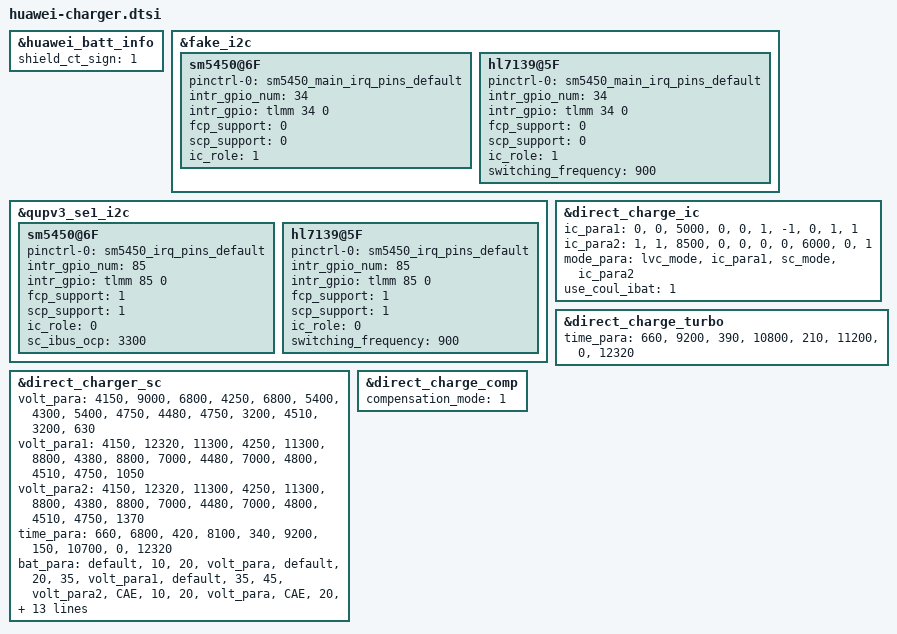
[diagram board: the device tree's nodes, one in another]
&huawei_batt_info {
    shield_ct_sign = <1>;
};

&fake_i2c {
	sm5450@6F{
		pinctrl-0 = <&sm5450_main_irq_pins_default>;
		intr_gpio_num = <34>; /* direct defined GPIO num */
		intr_gpio = <&tlmm 34 0>;
		fcp_support = <0>;
		scp_support = <0>;
		ic_role = <1>;
	};

	hl7139@5F {
		pinctrl-0 = <&sm5450_main_irq_pins_default>;
		intr_gpio_num = <34>; /* direct defined GPIO num */
		intr_gpio = <&tlmm 34 0>;
		fcp_support = <0>;
		scp_support = <0>;
		ic_role = <1>;
		switching_frequency = <900>;

	};
};

&qupv3_se1_i2c {
	sm5450@6F{
		pinctrl-0 = <&sm5450_irq_pins_default>;
		intr_gpio_num = <85>; /* direct defined GPIO num */
		intr_gpio = <&tlmm 85 0>;
		fcp_support = <1>;
		scp_support = <1>;
		ic_role = <0>;
	};

	hl7139@5F {
		pinctrl-0 = <&sm5450_irq_pins_default>;
		intr_gpio_num = <85>; /* direct defined GPIO num */
		intr_gpio = <&tlmm 85 0>;
		fcp_support = <1>;
		scp_support = <1>;
		ic_role = <0>;
		switching_frequency = <900>;

	};
};

&direct_charge_ic {
	/* ic_index  path_index  max_ibat  ibat_sample_point  vbat_sample_point */
	ic_para1 =
		"0", "0", "5000", "0", "0",
		"1", "-1", "0", "1", "1";
	ic_para2 =
		"1", "1", "8500", "0", "0",
		"0", "0", "6000", "0", "1";
	mode_para =
		"lvc_mode", "ic_para1",
		"sc_mode", "ic_para2";
        use_coul_ibat = <1>;
	status = "ok";
};

&direct_charger_sc {
	volt_para =
		"4150", "9000", "6800",
		"4250", "6800", "5400",
		"4300", "5400", "4750",
		"4480", "4750", "3200",
		"4510", "3200", "630";
	volt_para1 =
		"4150", "12320", "11300",
		"4250", "11300", "8800",
		"4380", "8800", "7000",
		"4480", "7000", "4800",
		"4510", "4750", "1050";
	volt_para2 =
		"4150", "12320", "11300",
		"4250", "11300", "8800",
		"4380", "8800", "7000",
		"4480", "7000", "4800",
		"4510", "4750", "1370";
	time_para =
		"660", "6800",
		"420", "8100",
		"340", "9200",
		"150", "10700",
		"0", "12320";
	bat_para =
		"default", "10", "20", "volt_para",
		"default", "20", "35", "volt_para1",
		"default", "35", "45", "volt_para2",
		"CAE", "10", "20", "volt_para",
		"CAE", "20", "35", "volt_para1",
		"CAE", "35", "45", "volt_para2",
		"CGL", "10", "20", "volt_para",
		"CGL", "20", "35", "volt_para1",
		"CGL", "35", "45", "volt_para2",
		"CDE", "10", "20", "volt_para",
                "CDE", "20", "35", "volt_para1",
                "CDE", "35", "45", "volt_para2";
	current_ratio =
		"3", "4", "10", "2", "-1",
		"3", "4", "9", "1", "8000",
		"0", "4", "9", "0", "0";
	vbat_error =
		"3", "120", "2", "-1",
		"3", "80", "1", "0";
	temp_para =
		"-32767", "10", "0",
		"10", "46", "12800",
		"46", "32767", "0";
	resist_para =
		"0", "260", "6000",
		"260", "450", "4000";
	std_resist_para =
		"0", "300", "0",
		"300", "450", "8000";
	second_resist_para =
		"0", "250", "0",
		"250", "450", "8000";
};

&direct_charge_turbo {
	status = "ok";
	time_para =
		"660", "9200",
		"390", "10800",
		"210", "11200",
		"0", "12320";
};

&qupv3_se1_i2c {
	sm5450@6F {
		sc_ibus_ocp = <3300>;
	};
};

&direct_charge_comp {
	compensation_mode = <1>;
};
